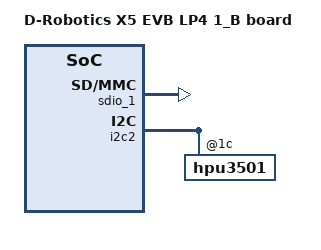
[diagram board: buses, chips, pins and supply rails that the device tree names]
// SPDX-License-Identifier: GPL-2.0
/*
 * dts for Sunrise5 EVB LP4 1_B board
 *
 * Copyright (C) 2024 D-Robotics Inc.
 *
 */

/dts-v1/;
#include "x5-evb.dtsi"

/ {
	model = "D-Robotics X5 EVB LP4 1_B board";
};

/* ANT_CTRL1 */
&hsio_iomuxc {
	hsio_gpio0_23: hsio_gpio0_23 {
		horizon,pins = <
			HSIO_SDIO_WP	HSIO_PINMUX_2	BIT_OFFSET8		MUX_ALT2	&pconf_output_high
		>;
	};

	pinctrl_sdio: sdiogrp {
		horizon,pins = <
			HSIO_SDIO_CLK	HSIO_PINMUX_0	BIT_OFFSET30	MUX_ALT0	&pconf_sd_sdio_pu_ds5_ipctrl
			HSIO_SDIO_CMD	HSIO_PINMUX_0	BIT_OFFSET28	MUX_ALT0	&pconf_sd_sdio_pu_ds3_ipctrl
			HSIO_SDIO_DATA0	HSIO_PINMUX_1	BIT_OFFSET0		MUX_ALT0	&pconf_sd_sdio_pu_ds3_ipctrl
			HSIO_SDIO_DATA1	HSIO_PINMUX_2	BIT_OFFSET30	MUX_ALT0	&pconf_sd_sdio_pu_ds3_ipctrl
			HSIO_SDIO_DATA2	HSIO_PINMUX_2	BIT_OFFSET28	MUX_ALT0	&pconf_sd_sdio_pu_ds3_ipctrl
			HSIO_SDIO_DATA3	HSIO_PINMUX_2	BIT_OFFSET26	MUX_ALT0	&pconf_sd_sdio_pu_ds3_ipctrl
		>;
	};
};

/* SDIO */
&sdio_1 {
	status = "okay";

	pinctrl-names = "default";
	pinctrl-0 = <&pinctrl_sdio &hsio_gpio0_23>;
	power-gpios = <&hs_gpio0_porta 23 GPIO_ACTIVE_HIGH>;
	toggle_interval_us = <100000>;
};


&i2c2 {
	status = "okay";

	hpu3501@1c {
		hpu3501-rtc {
			// In 1_B board, the RTC alarm and wakup gpio are both connected to AON_GPIO_PIN2,
			// so we don't suggest to use interrupt here, otherwise it will conflict with the wakeup gpio.
			// We don't suggest to use PMIC RTC function in evb 1_B.
			// Default status is "disabled".
			status = "disabled";
			opsel = <0>;
			// RTC_ALARM - AON_GPIO_PIN2
			pinctrl-names = "default";
			pinctrl-0 = <&aon_gpio_2>;
			interrupt-parent = <&aon_gpio_porta>;
			interrupts = <1 IRQ_TYPE_EDGE_RISING>;
		};
	};
};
